# STM32G564 register map
File version: 2.0.0
CPU: CM33 r0p4, little endian, MPU, FPU, 4 interrupt priority bits
Registers are 32-bit, read-write, reset 0x0 unless marked. A register's access mark holds for its fields unless they carry their own. Offsets are from the block's base; [hi:lo] are bit positions; {n}, {i} and the like mark numbered series; 'fields as' and 'values as' point back to an identical list.

## TIM1 — TIM address block description
Base 0x40012C00
Same registers: TIM8 0x40013400, TIM20 0x44000800, TIM1_S 0x50012C00, TIM8_S 0x50013400, TIM20_S 0x54000800
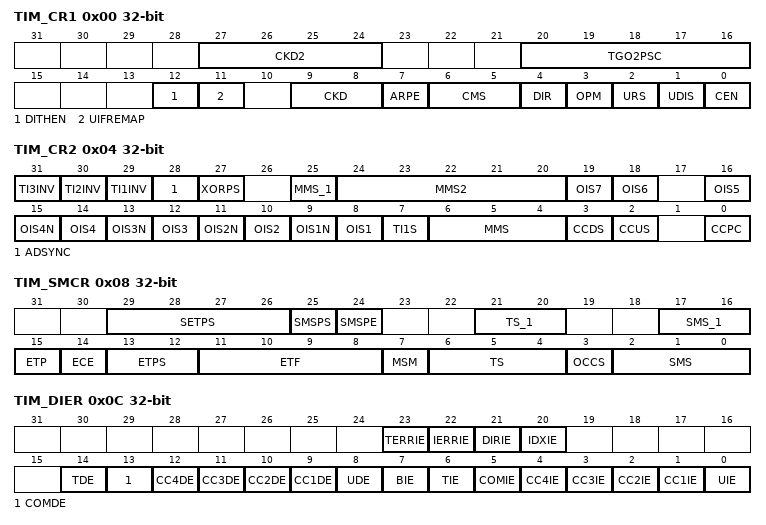
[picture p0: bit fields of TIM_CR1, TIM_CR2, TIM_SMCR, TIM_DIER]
0x00 TIM_CR1 — TIM control register 1
  [27:24] CKD2 — Clock division 2
    0=No Division; 1=tless thansub>DTS2less than/sub> = 4*tless thansub>DTSless than/sub>; 2=tless thansub>DTS2less than/sub> = 16*tless thansub>DTSless than/sub>; 3=tless thansub>DTS2less than/sub> = 64*tless thansub>DTSless than/sub>; 4=tless thansub>DTS2less than/sub> = 256*tless thansub>DTSless than/sub>; 5=tless thansub>DTS2less than/sub> = 1024*tless thansub>DTSless than/sub>; 6=tless thansub>DTS2less than/sub> = 4096*tless thansub>DTSless than/sub>; 7=tless thansub>DTS2less than/sub> = 16384*tless thansub>DTSless than/sub>; 8=tless thansub>DTS2less than/sub> = 65536*tless thansub>DTSless than/sub>; 9=tless thansub>DTS2less than/sub> = 262144*tless thansub>DTSless than/sub>
  [20:16] TGO2PSC — Trigger output 2 postcaler
  [12] DITHEN — Dithering enable
    0=Dithering disabled; 1=Dithering enabled
  [11] UIFREMAP — UIF status bit remapping
    0=No remapping. UIF status bit is not copied to TIMx_CNT register bit 31.; 1=Remapping enabled. UIF status bit is copied to TIMx_CNT register bit 31.
  [9:8] CKD — Clock division
    0=tless thansub>DTSless than/sub> = tless thansub>tim_ker_ckless than/sub>; 1=tless thansub>DTSless than/sub> = 2*tless thansub>tim_ker_ckless than/sub>; 2=tless thansub>DTSless than/sub> = 4*tless thansub>tim_ker_ckless than/sub>; 3=tless thansub>DTSless than/sub> = 8*tless thansub>tim_ker_ckless than/sub>
  [7] ARPE — Autoreload preload enable
    0=TIMx_ARR register is not buffered; 1=TIMx_ARR register is buffered
  [6:5] CMS — Center-aligned mode selection
    0=Edge-aligned mode. The counter counts up or down depending on the direction bit (DIR).; 1=Center-aligned mode 1. The counter counts up and down alternatively. Output compare interrupt flags of channels configured in output (CCxS = 00 in TIMx_CCMRx register) are set only when the counter is counting down.; 2=Center-aligned mode 2. The counter counts up and down alternatively. Output compare interrupt flags of channels configured in output (CCxS = 00 in TIMx_CCMRx register) are set only when the counter is counting up.; 3=Center-aligned mode 3. The counter counts up and down alternatively. Output compare interrupt flags of channels configured in output (CCxS = 00 in TIMx_CCMRx register) are set both when the counter is counting up or down.
  [4] DIR — Direction
    0=Counter used as upcounter; 1=Counter used as downcounter
  [3] OPM — One-pulse mode
    0=Counter is not stopped at update event; 1=Counter stops counting at the next update event (clearing the bit CEN)
  [2] URS — Update request source
    0=Any of the following events generate an update interrupt or DMA request if enabled. These events can be:; 1=Only counter overflow/underflow generates an update interrupt or DMA request if enabled
  [1] UDIS — Update disable
    0=UEV enabled. The Update (UEV) event is generated by one of the following events:; 1=UEV disabled. The Update event is not generated, shadow registers keep their value (ARR, PSC, CCRx). However the counter and the prescaler are reinitialized if the UG bit is set or if a hardware reset is received from the slave mode controller.
  [0] CEN — Counter enable
    0=Counter disabled; 1=Counter enabled
0x04 TIM_CR2 — TIM control register 2
  [31] TI3INV — tim_ti3 signal inversion on XOR gate input
    0=tim_ti3 non-inverted; 1=tim_ti3 inverted
  [30] TI2INV — tim_ti2 signal inversion on XOR gate input
    0=tim_ti2 non-inverted; 1=tim_ti2 inverted
  [29] TI1INV — tim_ti1 signal inversion on XOR gate input
    0=tim_ti1 non-inverted; 1=tim_ti1 inverted
  [28] ADSYNC — ADC synchronization
    0=The timer operates independently from the ADC; 1=The timer operation is synchronized with the ADC clock to provide jitter-free sampling point. This mode can be enabled only with specific ADC / timer clock relationship. Refer to Section204.3.37 for requirements.
  [27] XORPS — XOR gate position selection
    0=XOR gate placed before TI1 filter; 1=XOR gate placed after TI1, TI2 and TI3 filters
  [25] MMS_1 — MMS[3]
  [24:20] MMS2 — Master mode selection 2
    0=Reset - the UG bit from the TIMx_EGR register is used as trigger output (tim_trgo2). If the reset is generated by the trigger input (slave mode controller configured in reset mode), the signal on tim_trgo2 is delayed compared to the actual reset.; 1=Enable - the Counter Enable signal CNT_EN is used as trigger output (tim_trgo2). It is useful to start several timers at the same time or to control a window in which a slave timer is enabled. The Counter Enable signal is generated by a logic AND between the CEN control bit and the trigger input when configured in Gated mode. When the Counter Enable signal is controlled by the trigger input, there is a delay on tim_trgo2, except if the Master/Slave mode is selected (see the MSM bit description in TIMx_SMCR register).; 2=Update - the update event is selected as trigger output (tim_trgo2). For instance, a master timer can then be used as a prescaler for a slave timer.; 3=Compare pulse - the trigger output sends a positive pulse when the CC1IF flag is to be set (even if it was already high), as soon as a capture or compare match occurs (tim_trgo2); {v}=Compare - tim_oc{v-3}refc signal is used as trigger output (tim_trgo2) (v=4..9); 10=Compare Pulse - tim_oc4refc rising or falling edges generate pulses on tim_trgo2; 11=Compare pulse - tim_oc6refc rising or falling edges generate pulses on tim_trgo2; 12=Compare pulse - tim_oc4refc or tim_oc6refc rising edges generate pulses on tim_trgo2; 13=Compare pulse - tim_oc4refc rising or tim_oc6refc falling edges generate pulses on tim_trgo2; 14=Compare pulse - tim_oc5refc or tim_oc6refc rising edges generate pulses on tim_trgo2; 15=Compare pulse - tim_oc5refc rising or tim_oc6refc falling edges generate pulses on tim_trgo2; 16=Compare - tim_oc7refc signal is used as trigger output (tim_trgo2); 17=Compare Pulse - tim_oc7refc rising or falling edges generate pulses on tim_trgo2; 18=Compare Pulse tim_oc4refc or tim_oc7efc rising edges generate pulses on tim_trgo2; 19=Compare Pulse - tim_oc4refc rising or tim_oc7refc falling edges generate pulses on tim_trgo2; 20=Compare Pulse -tim_oc5refc or tim_oc7efc rising edges generate pulses on tim_trgo2; 21=Compare Pulse - tim_oc5refc rising or tim_oc7refc falling edges generate pulses on tim_trgo2; 22=Compare Pulse - tim_oc6refc or tim_oc7efc rising edges generate pulses on tim_trgo2; 23=Compare Pulse - tim_oc6refc rising or tim_oc7refc falling edges generate pulses on tim_trgo2
  [19] OIS7 — Output idle state 7 (tim_oc7 output)
  [18] OIS6 — Output idle state 6 (tim_oc6 output)
  [16] OIS5 — Output idle state 5 (tim_oc5 output)
  [15] OIS4N — Output idle state 4 (tim_oc4n output)
  [14] OIS4 — Output idle state 4 (tim_oc4 output)
  [13] OIS3N — Output idle state 3 (tim_oc3n output)
  [12] OIS3 — Output idle state 3 (tim_oc3n output)
  [11] OIS2N — Output idle state 2 (tim_oc2n output)
  [10] OIS2 — Output idle state 2 (tim_oc2 output)
  [9] OIS1N — Output idle state 1 (tim_oc1n output)
    0=tim_oc1n = 0 after a dead-time when MOE = 0; 1=tim_oc1n = 1 after a dead-time when MOE = 0
  [8] OIS1 — Output idle state 1 (tim_oc1 output)
    0=tim_oc1 = 0 (after a dead-time) when MOE = 0; 1=tim_oc1 = 1 (after a dead-time) when MOE = 0
  [7] TI1S — tim_ti1 selection
    0=The tim_ti1_in[15:0] multiplexer output is connected to tim_ti1 input; 1=tim_ti1_in[15:0], tim_ti2_in[15:0] and tim_ti3_in[15:0] multiplexers outputs are XORed and connected to the tim_ti1 input
  [6:4] MMS — MMS[2:0]: Master mode selection
    0=Reset - the UG bit from the TIMx_EGR register is used as trigger output (tim_trgo). If the reset is generated by the trigger input (slave mode controller configured in reset mode) then the signal on tim_trgo is delayed compared to the actual reset.; 1=Enable - the Counter Enable signal CNT_EN is used as trigger output (tim_trgo). It is useful to start several timers at the same time or to control a window in which a slave timer is enable. The Counter Enable signal is generated by a logic AND between CEN control bit and the trigger input when configured in gated mode. When the Counter Enable signal is controlled by the trigger input, there is a delay on tim_trgo, except if the master/slave mode is selected (see the MSM bit description in TIMx_SMCR register).; 2=Update - The update event is selected as trigger output (tim_trgo). For instance a master timer can then be used as a prescaler for a slave timer.; 3=Compare Pulse - The trigger output send a positive pulse when the CC1IF flag is to be set (even if it was already high), as soon as a capture or a compare match occurred. (tim_trgo).; {v}=Compare - tim_oc{v-3}refc signal is used as trigger output (tim_trgo) (v=4..7)
  [3] CCDS — Capture/compare DMA selection
    0=CCx DMA request sent when CCx event occurs; 1=CCx DMA requests sent when update event occurs
  [2] CCUS — Capture/compare control update selection
    0=When capture/compare control bits are preloaded (CCPC = 1), they are updated by setting the COMG bit only; 1=When capture/compare control bits are preloaded (CCPC = 1), they are updated by setting the COMG bit or when an rising edge occurs on tim_trgi
  [0] CCPC — Capture/compare preloaded control
    0=CCxE, CCxNE, CCxP, CCxNP and OCxM bits are not preloaded; 1=CCxE, CCxNE, CCxP, CCxNP and OCxM bits are preloaded, after having been written, they are updated only when a commutation event (COM) occurs (COMG bit set or rising edge detected on tim_trgi, depending on the CCUS bit)
0x08 TIM_SMCR — TIM slave mode control register
  [29:26] SETPS — Synchronous external trigger prescaler
  [25] SMSPS — SMS preload source
    0=The transfer is triggered by the Timer's Update event; 1=The transfer is triggered by the Index event
  [24] SMSPE — SMS preload enable
    0=SMS[4:0] bit field is not preloaded; 1=SMS[4:0] preload is enabled
  [21:20] TS_1 — TS[4:3]
  [17:16] SMS_1 — SMS[4:3]
  [15] ETP — External trigger polarity
    0=tim_etr_in is non-inverted, active at high level or rising edge; 1=tim_etr_in is inverted, active at low level or falling edge
  [14] ECE — External clock enable
    0=External clock mode 2 disabled; 1=External clock mode 2 enabled. The counter is clocked by any active edge on the tim_etrf signal.
  [13:12] ETPS — External trigger prescaler
    0=Prescaler OFF; 1=tim_etr_in frequency divided by 2; 2=tim_etr_in frequency divided by 4; 3=tim_etr_in frequency divided by 8
  [11:8] ETF — External trigger filter
    0=No filter, sampling is done at fless thansub>DTS2less than/sub>; 1=fless thansub>SAMPLINGless than/sub> = fless thansub>tim_ker_ckless than/sub>, N = 2; 2=fless thansub>SAMPLINGless than/sub> = fless thansub>tim_ker_ckless than/sub>, N = 4; 3=fless thansub>SAMPLINGless than/sub> = fless thansub>tim_ker_ckless than/sub>, N = 8; 4=fless thansub>SAMPLINGless than/sub> = fless thansub>DTS2less than/sub>/2, N = 6; 5=fless thansub>SAMPLINGless than/sub> = fless thansub>DTS2less than/sub>/2, N = 8; 6=fless thansub>SAMPLINGless than/sub> = fless thansub>DTS2less than/sub>/4, N = 6; 7=fless thansub>SAMPLINGless than/sub> = fless thansub>DTS2less than/sub>/4, N = 8; 8=fless thansub>SAMPLINGless than/sub> = fless thansub>DTS2less than/sub>/8, N = 6; 9=fless thansub>SAMPLINGless than/sub> = fless thansub>DTS2less than/sub>/8, N = 8; 10=fless thansub>SAMPLINGless than/sub> = fless thansub>DTS2less than/sub>/16, N = 5; 11=fless thansub>SAMPLINGless than/sub> = fless thansub>DTS2less than/sub>/16, N = 6; 12=fless thansub>SAMPLINGless than/sub> = fless thansub>DTS2less than/sub>/16, N = 8; 13=fless thansub>SAMPLINGless than/sub> = fless thansub>DTS2less than/sub>/32, N = 5; 14=fless thansub>SAMPLINGless than/sub> = fless thansub>DTS2less than/sub>/32, N = 6; 15=fless thansub>SAMPLINGless than/sub> = fless thansub>DTS2less than/sub>/32, N = 8
  [7] MSM — Master/slave mode
    0=No action; 1=The effect of an event on the trigger input (tim_trgi) is delayed to allow a perfect synchronization between the current timer and its slaves (through tim_trgo). It is useful if we want to synchronize several timers on a single external event.
  [6:4] TS — TS[2:0]: Trigger selection
    {v}=Internal trigger {v} (tim_itr{v}) (v=0..3); 4=tim_ti1 Edge Detector (tim_ti1f_ed); 5=Filtered Timer Input 1 (tim_ti1fp1); 6=Filtered Timer Input 2 (tim_ti2fp2); 7=External trigger input (tim_etrf)
  [3] OCCS — OCREF clear selection
    0=tim_ocref_clr_int is connected to the tim_ocref_clr input; 1=tim_ocref_clr_int is connected to tim_etrf
  [2:0] SMS — SMS[2:0]: Slave mode selection
    0=Slave mode disabled - if CEN = 1 then the prescaler is clocked directly by the internal clock; 1=Quadrature encoder mode 1, x2 mode- Counter counts up/down on tim_ti1fp1 edge depending on tim_ti2fp2 level; 2=Quadrature encoder mode 2, x2 mode - Counter counts up/down on tim_ti2fp2 edge depending on tim_ti1fp1 level; 3=Quadrature encoder mode 3, x4 mode - Counter counts up/down on both tim_ti1fp1 and tim_ti2fp2 edges depending on the level of the other input; 4=Reset mode - Rising edge of the selected trigger input (tim_trgi) reinitializes the counter and generates an update of the registers; 5=Gated mode - The counter clock is enabled when the trigger input (tim_trgi) is high. The counter stops (but is not reset) as soon as the trigger becomes low. Both start and stop of the counter are controlled.; 6=Trigger mode - The counter starts at a rising edge of the trigger tim_trgi (but it is not reset). Only the start of the counter is controlled.; 7=External Clock mode 1 - Rising edges of the selected trigger (tim_trgi) clock the counter
0x0C TIM_DIER — TIM DMA/interrupt enable register
  [23] TERRIE — Transition error interrupt enable
    0=Transition error interrupt disabled; 1=Transition error interrupt enabled
  [22] IERRIE — Index error interrupt enable
    0=Index error interrupt disabled; 1=Index error interrupt enabled
  [21] DIRIE — Direction change interrupt enable
    0=Direction Change interrupt disabled; 1=Direction Change interrupt enabled
  [20] IDXIE — Index interrupt enable
    0=Index interrupt disabled; 1=Index Change interrupt enabled
  [14] TDE — Trigger DMA request enable
    0=Trigger DMA request disabled; 1=Trigger DMA request enabled
  [13] COMDE — COM DMA request enable
    0=COM DMA request disabled; 1=COM DMA request enabled
  [n+8] CC{n}DE (n=1..4) — Capture/compare {n} DMA request enable
    0=CC{n} DMA request disabled; 1=CC{n} DMA request enabled
  [8] UDE — Update DMA request enable
    0=Update DMA request disabled; 1=Update DMA request enabled
  [7] BIE — Break interrupt enable
    0=Break interrupt disabled; 1=Break interrupt enabled
  [6] TIE — Trigger interrupt enable
    0=Trigger interrupt disabled; 1=Trigger interrupt enabled
  [5] COMIE — COM interrupt enable
    0=COM interrupt disabled; 1=COM interrupt enabled
  [n] CC{n}IE (n=1..4) — Capture/compare {n} interrupt enable
    0=CC{n} interrupt disabled; 1=CC{n} interrupt enabled
  [0] UIE — Update interrupt enable
    0=Update interrupt disabled; 1=Update interrupt enabled
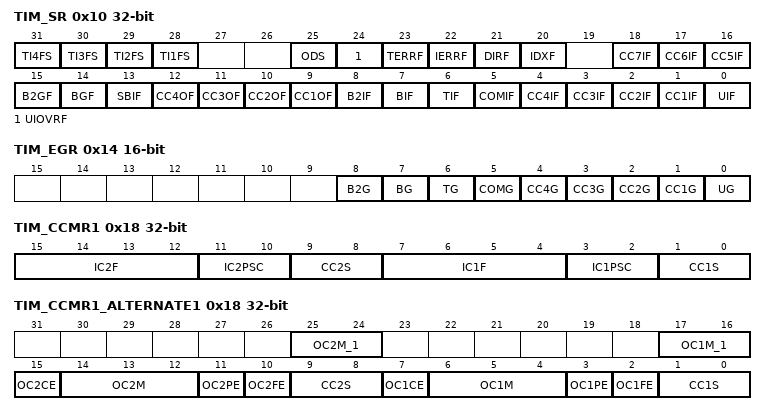
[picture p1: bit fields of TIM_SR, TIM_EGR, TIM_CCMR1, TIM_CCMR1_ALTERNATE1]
0x10 TIM_SR — TIM status register
  [n+27] TI{n}FS ro (n=1..4) — tim_ti{n}f status
    0=tim_ti{n}f signal is low; 1=tim_ti{n}f signal is high
  [25] ODS ro — Output disable status
    0=Idle state: break was triggered (or MOE was written to 0), and OIS states are forced on tim_ocx and tim_ocxn outputs; 1=Disabled state: break2 was triggered, tim_ocx and tim_ocxn outputs are inactive
  [24] UIOVRF — Update Interrupt Overrun flag
    0=No Update Interrupt Overrun; 1=Update Interrupt Overrun
  [23] TERRF — Transition error interrupt flag
    0=No encoder transition error has been detected; 1=An encoder transition error has been detected
  [22] IERRF — Index error interrupt flag
    0=No index error has been detected; 1=An index error has been detected
  [21] DIRF — Direction change interrupt flag
    0=No direction change; 1=Direction change
  [20] IDXF — Index interrupt flag
    0=No index event occurred; 1=An index event has occurred
  [18] CC7IF — Compare 7 interrupt flag
  [17] CC6IF — Compare 6 interrupt flag
  [16] CC5IF — Compare 5 interrupt flag
  [15] B2GF — Break 2 generation flag
    0=No break 2 event occurred; 1=A break 2 event was forced with the B2G bit
  [14] BGF — Break generation flag
    0=No break event occurred; 1=A break event was forced with the BG bit
  [13] SBIF — System break interrupt flag
    0=No break event occurred; 1=An active level has been detected on the system break input. An interrupt is generated if BIE = 1 in the TIMx_DIER register.
  [12] CC4OF — Capture/compare 4 overcapture flag
  [11] CC3OF — Capture/compare 3 overcapture flag
  [10] CC2OF — Capture/compare 2 overcapture flag
  [9] CC1OF — Capture/compare 1 overcapture flag
    0=No overcapture has been detected; 1=The counter value has been captured in TIMx_CCR1 register while CC1IF flag was already set
  [8] B2IF — Break 2 interrupt flag
    0=No break event occurred; 1=An active level has been detected on the break 2 input. An interrupt is generated if BIE=1 in the TIMx_DIER register.
  [7] BIF — Break interrupt flag
    0=No break event occurred; 1=An active level has been detected on the break input. An interrupt is generated if BIE = 1 in the TIMx_DIER register.
  [6] TIF — Trigger interrupt flag
    0=No trigger event occurred; 1=Trigger interrupt pending
  [5] COMIF — COM interrupt flag
    0=No COM event occurred; 1=COM interrupt pending
  [4] CC4IF — Capture/compare 4 interrupt flag
  [3] CC3IF — Capture/compare 3 interrupt flag
  [2] CC2IF — Capture/compare 2 interrupt flag
  [1] CC1IF — Capture/compare 1 interrupt flag
    0=No compare match / No input capture occurred; 1=A compare match or an input capture occurred
  [0] UIF — Update interrupt flag
    0=No update occurred; 1=Update interrupt pending. This bit is set by hardware when the registers are updated:
0x14 TIM_EGR 16-bit wo — TIM event generation register
  [8] B2G — Break 2 generation
    0=No action; 1=A break 2 event is generated. MOE bit is cleared and B2IF flag is set. Related interrupt can occur if enabled.
  [7] BG — Break generation
    0=No action; 1=A break event is generated. MOE bit is cleared and BIF flag is set. Related interrupt or DMA transfer can occur if enabled.
  [6] TG — Trigger generation
    0=No action; 1=The TIF flag is set in TIMx_SR register. Related interrupt or DMA transfer can occur if enabled.
  [5] COMG — Capture/compare control update generation
    0=No action; 1=CCxE, CCxNE and OCxM bits update (providing CCPC bit is set)
  [4] CC4G — Capture/compare 4 generation
  [3] CC3G — Capture/compare 3 generation
  [2] CC2G — Capture/compare 2 generation
  [1] CC1G — Capture/compare 1 generation
    0=No action; 1=A capture/compare event is generated on channel 1:
  [0] UG — Update generation
    0=No action; 1=Reinitialize the counter and generates an update of the registers. Note that the prescaler counter is cleared too (anyway the prescaler ratio is not affected). The counter is cleared if the center-aligned mode is selected or if DIR = 0 (upcounting), else it takes the autoreload value (TIMx_ARR) if DIR = 1 (downcounting).
0x18 TIM_CCMR1 — TIM capture/compare mode register 1
  [15:12] IC2F — Input capture 2 filter
  [11:10] IC2PSC — Input capture 2 prescaler
  [9:8] CC2S — Capture/compare 2 selection
    0=CC2 channel is configured as output; 1=CC2 channel is configured as input, tim_ic2 is mapped on tim_ti2; 2=CC2 channel is configured as input, tim_ic2 is mapped on tim_ti1; 3=CC2 channel is configured as input, tim_ic2 is mapped on tim_trc. This mode is working only if an internal trigger input is selected through TS bit (TIMx_SMCR register)
  [7:4] IC1F — Input capture 1 filter
    values as TIM_SMCR.ETF
  [3:2] IC1PSC — Input capture 1 prescaler
    0=no prescaler, capture is done each time an edge is detected on the capture input; 1=capture is done once every 2 events; 2=capture is done once every 4 events; 3=capture is done once every 8 events
  [1:0] CC1S — Capture/compare 1 Selection
    0=CC1 channel is configured as output; 1=CC1 channel is configured as input, tim_ic1 is mapped on tim_ti1; 2=CC1 channel is configured as input, tim_ic1 is mapped on tim_ti2; 3=CC1 channel is configured as input, tim_ic1 is mapped on tim_trc. This mode is working only if an internal trigger input is selected through TS bit (TIMx_SMCR register)
0x18 TIM_CCMR1_ALTERNATE1 (alternate view of TIM_CCMR1) — TIM capture/compare mode register 1
  [25:24] OC2M_1 — OC2M[4:3]
  [17:16] OC1M_1 — OC1M[4:3]
  [15] OC2CE — Output compare 2 clear enable
    0=tim_oc2ref is not affected by the tim_ocref_clr_int signal; 1=tim_oc2ref is cleared as soon as a High level is detected on tim_ocref_clr_int signal (tim_ocref_clr input or tim_etrf input)
  [14:12] OC2M — OC2M[2:0]: Output compare 2 mode
  [11] OC2PE — Output compare 2 preload enable
    0=Preload register on TIMx_CCR2 disabled. TIMx_CCR2 can be written at anytime, the new value is taken in account immediately.; 1=Preload register on TIMx_CCR2 enabled. Read/Write operations access the preload register. TIMx_CCR2 preload value is loaded in the active register at each update event.
  [10] OC2FE — Output compare 2 fast enable
    0=CC2 behaves normally depending on counter and CCR2 values even when the trigger is ON. The minimum delay to activate CC2 output when an edge occurs on the trigger input is 5 clock cycles.; 1=An active edge on the trigger input acts like a compare match on CC2 output. Then, OC is set to the compare level independently from the result of the comparison. Delay to sample the trigger input and to activate CC2 output is reduced to 3 clock cycles. OCFE acts only if the channel is configured in PWM1 or PWM2 mode.
  [9:8] CC2S — Capture/compare 2 selection
    0=CC2 channel is configured as output; 1=CC2 channel is configured as input, tim_ic2 is mapped on tim_ti2; 2=CC2 channel is configured as input, tim_ic2 is mapped on tim_ti1; 3=CC2 channel is configured as input, tim_ic2 is mapped on tim_trc. This mode is working only if an internal trigger input is selected through the TS bit (TIMx_SMCR register)
  [7] OC1CE — Output compare 1 clear enable
    0=tim_oc1ref is not affected by the tim_ocref_clr_int signal; 1=tim_oc1ref is cleared as soon as a High level is detected on tim_ocref_clr_int signal (tim_ocref_clr input or tim_etrf input)
  [6:4] OC1M — OC1M[2:0]: Output compare 1 mode
    0=Frozen - The comparison between the output compare register TIMx_CCR1 and the counter TIMx_CNT has no effect on the outputs.This mode can be used when the timer serves as a software timebase. When the frozen mode is enabled during timer operation, the output keeps the state (active or inactive) it had before entering the frozen state.; 1=Set channel 1 to active level on match. tim_oc1ref signal is forced high when the counter TIMx_CNT matches the capture/compare register 1 (TIMx_CCR1).; 2=Set channel 1 to inactive level on match. tim_oc1ref signal is forced low when the counter TIMx_CNT matches the capture/compare register 1 (TIMx_CCR1).; 3=Toggle - tim_oc1ref toggles when TIMx_CNT = TIMx_CCR1; 4=Force inactive level - tim_oc1ref is forced low; 5=Force active level - tim_oc1ref is forced high; 6=PWM mode 1 - In upcounting, channel 1 is active as long as TIMx_CNTless thanTIMx_CCR1 else inactive. In downcounting, channel 1 is inactive (tim_oc1ref = 0) as long as TIMx_CNT>TIMx_CCR1 else active (tim_oc1ref = 1).; 7=PWM mode 2 - In upcounting, channel 1 is inactive as long as TIMx_CNTless thanTIMx_CCR1 else active. In downcounting, channel 1 is active as long as TIMx_CNT>TIMx_CCR1 else inactive.
  [3] OC1PE — Output compare 1 preload enable
    0=Preload register on TIMx_CCR1 disabled. TIMx_CCR1 can be written at anytime, the new value is taken in account immediately.; 1=Preload register on TIMx_CCR1 enabled. Read/Write operations access the preload register. TIMx_CCR1 preload value is loaded in the active register at each update event.
  [2] OC1FE — Output compare 1 fast enable
    0=CC1 behaves normally depending on counter and CCR1 values even when the trigger is ON. The minimum delay to activate CC1 output when an edge occurs on the trigger input is 5 clock cycles.; 1=An active edge on the trigger input acts like a compare match on CC1 output. Then, OC is set to the compare level independently from the result of the comparison. Delay to sample the trigger input and to activate CC1 output is reduced to 3 clock cycles. OCFE acts only if the channel is configured in PWM1 or PWM2 mode.
  [1:0] CC1S — Capture/compare 1 selection
    values as TIM_CCMR1.CC1S
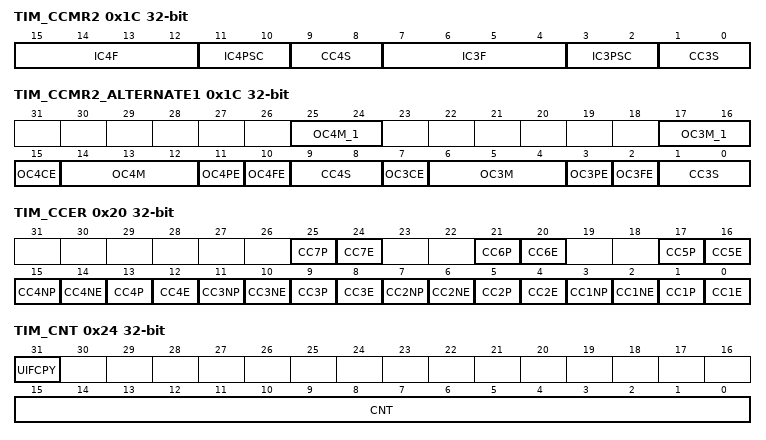
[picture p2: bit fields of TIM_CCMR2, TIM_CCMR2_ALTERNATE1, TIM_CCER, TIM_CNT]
0x1C TIM_CCMR2 — TIM capture/compare mode register 2
  [15:12] IC4F — Input capture 4 filter
  [11:10] IC4PSC — Input capture 4 prescaler
  [9:8] CC4S — Capture/compare 4 selection
    0=CC4 channel is configured as output; 1=CC4 channel is configured as input, tim_ic4 is mapped on tim_ti4; 2=CC4 channel is configured as input, tim_ic4 is mapped on tim_ti3; 3=CC4 channel is configured as input, tim_ic4 is mapped on tim_trc. This mode is working only if an internal trigger input is selected through TS bit (TIMx_SMCR register)
  [7:4] IC3F — Input capture 3 filter
    values as TIM_SMCR.ETF
  [3:2] IC3PSC — Input capture 3 prescaler
    values as TIM_CCMR1.IC1PSC
  [1:0] CC3S — Capture/compare 3 selection
    0=CC3 channel is configured as output; 1=CC3 channel is configured as input, tim_ic3 is mapped on tim_ti3; 2=CC3 channel is configured as input, tim_ic3 is mapped on tim_ti4; 3=CC3 channel is configured as input, tim_ic3 is mapped on tim_trc. This mode is working only if an internal trigger input is selected through TS bit (TIMx_SMCR register)
0x1C TIM_CCMR2_ALTERNATE1 (alternate view of TIM_CCMR2) — TIM capture/compare mode register 2
  [25:24] OC4M_1 — OC4M[4:3]
  [17:16] OC3M_1 — OC3M[4:3]
  [15] OC4CE — Output compare 4 clear enable
    0=tim_oc4ref is not affected by the tim_ocref_clr_int signal; 1=tim_oc4ref is cleared as soon as a High level is detected on tim_ocref_clr_int signal (tim_ocref_clr input or tim_etrf input)
  [14:12] OC4M — OC4M[2:0]: Output compare 4 mode
  [11] OC4PE — Output compare 4 preload enable
    0=Preload register on TIMx_CCR4 disabled. TIMx_CCR4 can be written at anytime, the new value is taken in account immediately.; 1=Preload register on TIMx_CCR4 enabled. Read/Write operations access the preload register. TIMx_CCR4 preload value is loaded in the active register at each update event.
  [10] OC4FE — Output compare 4 fast enable
    0=CC4 behaves normally depending on counter and CCR4 values even when the trigger is ON. The minimum delay to activate CC4 output when an edge occurs on the trigger input is 5 clock cycles.; 1=An active edge on the trigger input acts like a compare match on CC4 output. Then, OC is set to the compare level independently from the result of the comparison. Delay to sample the trigger input and to activate CC4 output is reduced to 3 clock cycles. OCFE acts only if the channel is configured in PWM1 or PWM2 mode.
  [9:8] CC4S — Capture/compare 4 selection
    values as TIM_CCMR2.CC4S
  [7] OC3CE — Output compare 3 clear enable
    0=tim_oc3ref is not affected by the tim_ocref_clr_int signal; 1=tim_oc3ref is cleared as soon as a High level is detected on tim_ocref_clr_int signal (tim_ocref_clr input or tim_etrf input)
  [6:4] OC3M — OC3M[2:0]: Output compare 3 mode
    0=Frozen - The comparison between the output compare register TIMx_CCR3 and the counter TIMx_CNT has no effect on the outputs.(this mode is used to generate a timing base); 1=Set channel 3 to active level on match. tim_oc3ref signal is forced high when the counter TIMx_CNT matches the capture/compare register 3 (TIMx_CCR3).; 2=Set channel 3 to inactive level on match. tim_oc3ref signal is forced low when the counter TIMx_CNT matches the capture/compare register 3 (TIMx_CCR3).; 3=Toggle - tim_oc3ref toggles when TIMx_CNT = TIMx_CCR3; 4=Force inactive level - tim_oc3ref is forced low; 5=Force active level - tim_oc3ref is forced high; 6=PWM mode 1 - In upcounting, channel 3 is active as long as TIMx_CNTless thanTIMx_CCR3 else inactive. In downcounting, channel 3 is inactive (tim_oc3ref = 0) as long as TIMx_CNT>TIMx_CCR3 else active (tim_oc3ref = 1).; 7=PWM mode 2 - In upcounting, channel 3 is inactive as long as TIMx_CNTless thanTIMx_CCR3 else active. In downcounting, channel 3 is active as long as TIMx_CNT>TIMx_CCR3 else inactive.
  [3] OC3PE — Output compare 3 preload enable
    0=Preload register on TIMx_CCR3 disabled. TIMx_CCR3 can be written at anytime, the new value is taken in account immediately.; 1=Preload register on TIMx_CCR3 enabled. Read/Write operations access the preload register. TIMx_CCR3 preload value is loaded in the active register at each update event.
  [2] OC3FE — Output compare 3 fast enable
    0=CC3 behaves normally depending on counter and CCR3 values even when the trigger is ON. The minimum delay to activate CC3 output when an edge occurs on the trigger input is 5 clock cycles.; 1=An active edge on the trigger input acts like a compare match on CC3 output. Then, OC is set to the compare level independently from the result of the comparison. Delay to sample the trigger input and to activate CC3 output is reduced to 3 clock cycles. OCFE acts only if the channel is configured in PWM1 or PWM2 mode.
  [1:0] CC3S — Capture/compare 3 selection
    values as TIM_CCMR2.CC3S
0x20 TIM_CCER — TIM capture/compare enable register
  [4n-3] CC{n}P (n=2..7) — Capture/compare {n} output polarity
  [4n-4] CC{n}E (n=2..7) — Capture/compare {n} output enable
  [15] CC4NP — Capture/compare 4 complementary output polarity
  [14] CC4NE — Capture/compare 4 complementary output enable
  [11] CC3NP — Capture/compare 3 complementary output polarity
  [10] CC3NE — Capture/compare 3 complementary output enable
  [7] CC2NP — Capture/compare 2 complementary output polarity
  [6] CC2NE — Capture/compare 2 complementary output enable
  [3] CC1NP — Capture/compare 1 complementary output polarity
    0=tim_oc1n active high; 1=tim_oc1n active low
  [2] CC1NE — Capture/compare 1 complementary output enable
    0=Off - tim_oc1n is not active. tim_oc1n level is then function of MOE, OSSI, OSSR, OIS1, OIS1N and CC1E bits.; 1=On - tim_oc1n signal is output on the corresponding output pin depending on MOE, OSSI, OSSR, OIS1, OIS1N and CC1E bits
  [1] CC1P — Capture/compare 1 output polarity
    0=OC1 active high (output mode) / Edge sensitivity selection (input mode, see below); 1=OC1 active low (output mode) / Edge sensitivity selection (input mode, see below)
  [0] CC1E — Capture/compare 1 output enable
    0=Capture mode disabled / OC1 is not active (see below); 1=Capture mode enabled / OC1 signal is output on the corresponding output pin
0x24 TIM_CNT — TIM counter
  [31] UIFCPY ro — UIF copy
  [15:0] CNT — Counter value
0x28 TIM_PSC 16-bit — TIM prescaler
  [15:0] PSC — Prescaler value
0x2C TIM_ARR reset 0xFFFF — TIM autoreload register
  [19:0] ARR — Autoreload value
0x30 TIM_RCR 16-bit — TIM repetition counter register
  [15:0] REP — Repetition counter reload value
0x34 TIM_CCR1 — TIM capture/compare register 1
  [19:0] CCR1 — Capture/compare 1 value
0x38 TIM_CCR2 — TIM capture/compare register 2
  [19:0] CCR2 — Capture/compare 2 value
0x3C TIM_CCR3 — TIM capture/compare register 3
  [19:0] CCR3 — Capture/compare value
0x40 TIM_CCR4 — TIM capture/compare register 4
  [19:0] CCR4 — Capture/compare value
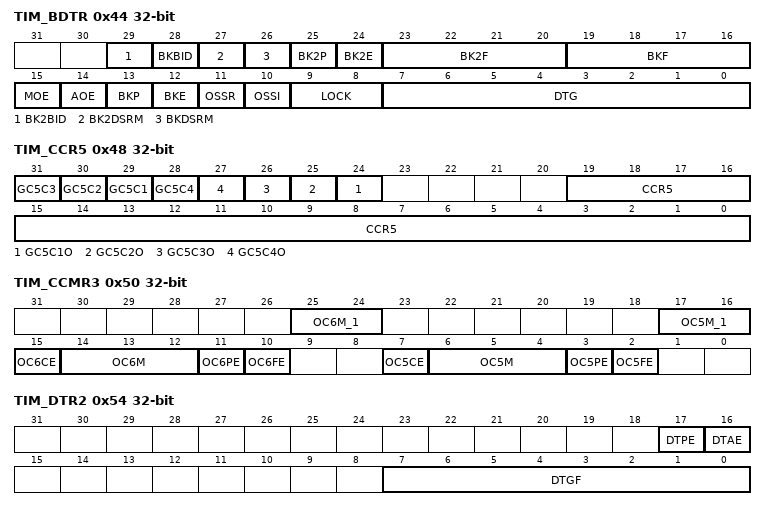
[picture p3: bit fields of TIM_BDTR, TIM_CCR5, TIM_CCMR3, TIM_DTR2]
0x44 TIM_BDTR — TIM break and dead-time register
  [29] BK2BID — Break2 bidirectional
  [28] BKBID — Break bidirectional
    0=Break input tim_brk in input mode; 1=Break input tim_brk in bidirectional mode
  [27] BK2DSRM — Break2 disarm
  [26] BKDSRM — Break disarm
    0=Break input tim_brk is armed; 1=Break input tim_brk is disarmed
  [25] BK2P — Break 2 polarity
    0=Break input tim_brk2 is active low; 1=Break input tim_brk2 is active high
  [24] BK2E — Break 2 enable
    0=Break2 function disabled; 1=Break2 function enabled
  [23:20] BK2F — Break 2 filter
    0=No filter, tim_brk2 acts asynchronously; 1=fless thansub>SAMPLINGless than/sub> = fless thansub>tim_ker_ckless than/sub>, N = 2; 2=fless thansub>SAMPLINGless than/sub> = fless thansub>tim_ker_ckless than/sub>, N = 4; 3=fless thansub>SAMPLINGless than/sub> = fless thansub>tim_ker_ckless than/sub>, N = 8; 4=fless thansub>SAMPLINGless than/sub> = fless thansub>DTSless than/sub>/2, N = 6; 5=fless thansub>SAMPLINGless than/sub> = fless thansub>DTSless than/sub>/2, N = 8; 6=fless thansub>SAMPLINGless than/sub> = fless thansub>DTSless than/sub>/4, N = 6; 7=fless thansub>SAMPLINGless than/sub> = fless thansub>DTSless than/sub>/4, N = 8; 8=fless thansub>SAMPLINGless than/sub> = fless thansub>DTSless than/sub>/8, N = 6; 9=fless thansub>SAMPLINGless than/sub> = fless thansub>DTSless than/sub>/8, N = 8; 10=fless thansub>SAMPLINGless than/sub> = fless thansub>DTSless than/sub>/16, N = 5; 11=fless thansub>SAMPLINGless than/sub> = fless thansub>DTSless than/sub>/16, N = 6; 12=fless thansub>SAMPLINGless than/sub> = fless thansub>DTSless than/sub>/16, N = 8; 13=fless thansub>SAMPLINGless than/sub> = fless thansub>DTSless than/sub>/32, N = 5; 14=fless thansub>SAMPLINGless than/sub> = fless thansub>DTSless than/sub>/32, N = 6; 15=fless thansub>SAMPLINGless than/sub> = fless thansub>DTSless than/sub>/32, N = 8
  [19:16] BKF — Break filter
    0=No filter, tim_brk acts asynchronously; 1=fless thansub>SAMPLINGless than/sub> = fless thansub>tim_ker_ckless than/sub>, N = 2; 2=fless thansub>SAMPLINGless than/sub> = fless thansub>tim_ker_ckless than/sub>, N = 4; 3=fless thansub>SAMPLINGless than/sub> = fless thansub>tim_ker_ckless than/sub>, N = 8; 4=fless thansub>SAMPLINGless than/sub> = fless thansub>DTSless than/sub>/2, N = 6; 5=fless thansub>SAMPLINGless than/sub> = fless thansub>DTSless than/sub>/2, N = 8; 6=fless thansub>SAMPLINGless than/sub> = fless thansub>DTSless than/sub>/4, N = 6; 7=fless thansub>SAMPLINGless than/sub> = fless thansub>DTSless than/sub>/4, N = 8; 8=fless thansub>SAMPLINGless than/sub> = fless thansub>DTSless than/sub>/8, N = 6; 9=fless thansub>SAMPLINGless than/sub> = fless thansub>DTSless than/sub>/8, N = 8; 10=fless thansub>SAMPLINGless than/sub> = fless thansub>DTSless than/sub>/16, N = 5; 11=fless thansub>SAMPLINGless than/sub> = fless thansub>DTSless than/sub>/16, N = 6; 12=fless thansub>SAMPLINGless than/sub> = fless thansub>DTSless than/sub>/16, N = 8; 13=fless thansub>SAMPLINGless than/sub> = fless thansub>DTSless than/sub>/32, N = 5; 14=fless thansub>SAMPLINGless than/sub> = fless thansub>DTSless than/sub>/32, N = 6; 15=fless thansub>SAMPLINGless than/sub> = fless thansub>DTSless than/sub>/32, N = 8
  [15] MOE — Main output enable
    0=In response to a break 2 event. OC and OCN outputs are disabled; 1=OC and OCN outputs are enabled if their respective enable bits are set (CCxE, CCxNE in TIMx_CCER register)
  [14] AOE — Automatic output enable
    0=MOE can be set only by software; 1=MOE can be set by software or automatically at the next update event (if none of the break inputs tim_brk and tim_brk2 is active)
  [13] BKP — Break polarity
    0=Break input tim_brk is active low; 1=Break input tim_brk is active high
  [12] BKE — Break enable
    0=Break function disabled; 1=Break function enabled
  [11] OSSR — Off-state selection for Run mode
    0=When inactive, OC/OCN outputs are disabled (the timer releases the output control which is taken over by the GPIO logic, which forces a Hi-Z state); 1=When inactive, OC/OCN outputs are enabled with their inactive level as soon as CCxE = 1 or CCxNE = 1 (the output is still controlled by the timer)
  [10] OSSI — Off-state selection for idle mode
    0=When inactive, OC/OCN outputs are disabled (the timer releases the output control which is taken over by the GPIO logic and which imposes a Hi-Z state); 1=When inactive, OC/OCN outputs are first forced with their inactive level then forced to their idle level after the deadtime. The timer maintains its control over the output.
  [9:8] LOCK — Lock configuration
    0=LOCK OFF - No bit is write protected; 1=LOCK Level 1 = DTG bits in TIMx_BDTR register, OISx and OISxN bits in TIMx_CR2 register and BKBID/BK2BID/BKE/BKP/AOE bits in TIMx_BDTR register can no longer be written; 2=LOCK Level 2 = LOCK Level 1 + CC Polarity bits (CCxP/CCxNP bits in TIMx_CCER register, as long as the related channel is configured in output through the CCxS bits) as well as OSSR and OSSI bits can no longer be written; 3=LOCK Level 3 = LOCK Level 2 + CC Control bits (OCxM and OCxPE bits in TIMx_CCMRx registers, as long as the related channel is configured in output through the CCxS bits) can no longer be written
  [7:0] DTG — Dead-time generator setup
0x48 TIM_CCR5 — TIM capture/compare register 5
  [31] GC5C3 — Group channel 5 and channel 3
    0=No effect of tim_oc5ref on tim_oc3refc; 1=tim_oc3refc is the logical AND of tim_oc3ref and tim_oc5ref
  [30] GC5C2 — Group channel 5 and channel 2
    0=No effect of tim_oc5ref on tim_oc2refc; 1=tim_oc2refc is the logical AND of tim_oc2ref and tim_oc5ref
  [29] GC5C1 — Group channel 5 and channel 1
    0=No effect of oc5ref on oc1refc; 1=oc1refc is the logical AND of oc1ref and oc5ref
  [28] GC5C4 — Group channel 5 and channel 4
    0=No effect of oc5ref on oc4refc; 1=oc4refc is the logical AND of oc4ref and oc5ref
  [n+23] GC5C{n}O (n=1..4) — Group channel 5 and channel {n} (ORed)
    0=No effect of oc5ref on oc{n}refc; 1=oc4refc is the logical OR of oc{n}ref and oc5ref
  [19:0] CCR5 — compare 5 value
0x4C TIM_CCR6 — TIM capture/compare register 6
  [19:0] CCR6 — Compare 6 value
0x50 TIM_CCMR3 — TIM capture/compare mode register 3
  [25:24] OC6M_1 — OC6M[4:3]
  [17:16] OC5M_1 — OC5M[4:3]
  [15] OC6CE — Output compare 6 clear enable
    0=tim_oc6ref is not affected by the tim_ocref_clr_int signal; 1=tim_oc6ref is cleared as soon as a High level is detected on tim_ocref_clr_int signal (tim_ocref_clr input or tim_etrf input)
  [14:12] OC6M — OC6M[2:0]: Output compare 6 mode
  [11] OC6PE — Output compare 6 preload enable
    0=Preload register on TIMx_CCR6 disabled. TIMx_CCR6 can be written at anytime, the new value is taken in account immediately.; 1=Preload register on TIMx_CCR6 enabled. Read/Write operations access the preload register. TIMx_CCR6 preload value is loaded in the active register at each update event.
  [10] OC6FE — Output compare 6 fast enable
    0=CC6 behaves normally depending on counter and CCR6 values even when the trigger is ON. The minimum delay to activate CC6 output when an edge occurs on the trigger input is 5 clock cycles.; 1=An active edge on the trigger input acts like a compare match on CC6 output. Then, OC is set to the compare level independently from the result of the comparison. Delay to sample the trigger input and to activate CC6 output is reduced to 3 clock cycles. OCFE acts only if the channel is configured in PWM1 or PWM2 mode.
  [7] OC5CE — Output compare 5 clear enable
    0=tim_oc5ref is not affected by the tim_ocref_clr_int signal; 1=tim_oc5ref is cleared as soon as a High level is detected on tim_ocref_clr_int signal (tim_ocref_clr input or tim_etrf input)
  [6:4] OC5M — OC5M[2:0]: Output compare 5 mode
    0=Frozen - The comparison between the output compare register TIMx_CCR5 and the counter TIMx_CNT has no effect on the outputs.(this mode is used to generate a timing base); 1=Set channel 5 to active level on match. tim_oc5ref signal is forced high when the counter TIMx_CNT matches the capture/compare register 5 (TIMx_CCR5).; 2=Set channel 5 to inactive level on match. tim_oc5ref signal is forced low when the counter TIMx_CNT matches the capture/compare register 5 (TIMx_CCR5).; 3=Toggle - tim_oc5ref toggles when TIMx_CNT = TIMx_CCR5; 4=Force inactive level - tim_oc5ref is forced low; 5=Force active level - tim_oc5ref is forced high; 6=PWM mode 1 - In upcounting, channel 5 is active as long as TIMx_CNTless thanTIMx_CCR5 else inactive. In downcounting, channel 5 is inactive (tim_oc5ref = 0) as long as TIMx_CNT>TIMx_CCR5 else active (tim_oc5ref = 1).; 7=PWM mode 2 - In upcounting, channel 5 is inactive as long as TIMx_CNTless thanTIMx_CCR5 else active. In downcounting, channel 5 is active as long as TIMx_CNT>TIMx_CCR5 else inactive.
  [3] OC5PE — Output compare 5 preload enable
    0=Preload register on TIMx_CCR5 disabled. TIMx_CCR5 can be written at anytime, the new value is taken in account immediately.; 1=Preload register on TIMx_CCR5 enabled. Read/Write operations access the preload register. TIMx_CCR5 preload value is loaded in the active register at each update event.
  [2] OC5FE — Output compare 5 fast enable
    0=CC5 behaves normally depending on counter and CCR5 values even when the trigger is ON. The minimum delay to activate CC5 output when an edge occurs on the trigger input is 5 clock cycles.; 1=An active edge on the trigger input acts like a compare match on CC5 output. Then, OC is set to the compare level independently from the result of the comparison. Delay to sample the trigger input and to activate CC5 output is reduced to 3 clock cycles. OCFE acts only if the channel is configured in PWM1 or PWM2 mode.
0x54 TIM_DTR2 — TIM timer deadtime register 2
  [17] DTPE — Deadtime preload enable
    0=Deadtime value is not preloaded; 1=Deadtime value preload is enabled
  [16] DTAE — Deadtime asymmetric enable
    0=Deadtime on rising and falling edges are identical, and defined with DTG[7:0] register; 1=Deadtime on rising edge is defined with DTG[7:0] register and deadtime on falling edge is defined with DTGF[7:0] bits
  [7:0] DTGF — Dead-time falling edge generator setup
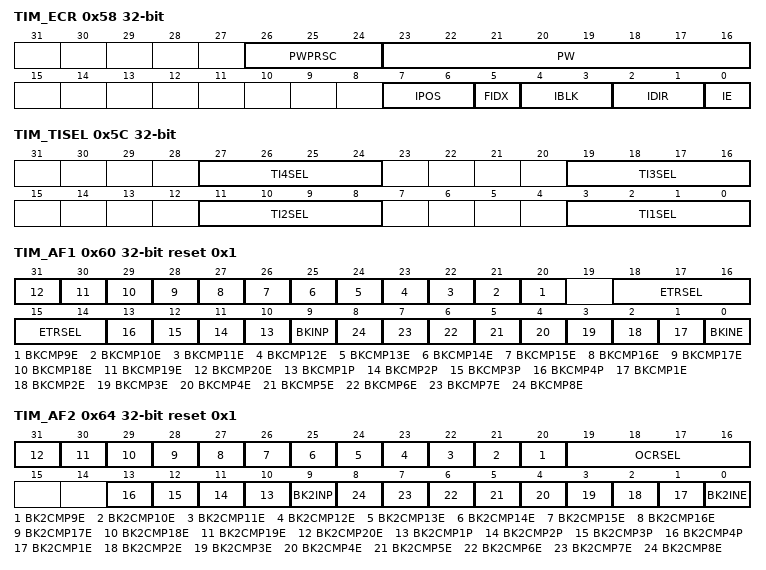
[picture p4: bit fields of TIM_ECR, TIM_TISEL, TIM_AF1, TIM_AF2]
0x58 TIM_ECR — TIM timer encoder control register
  [26:24] PWPRSC — Pulse width prescaler
  [23:16] PW — Pulse width
  [7:6] IPOS — Index positioning
    0=Index resets the counter when AB = 00; 1=Index resets the counter when AB = 01; 2=Index resets the counter when AB = 10; 3=Index resets the counter when AB = 11
  [5] FIDX — First index
    0=Index is always active; 1=the first Index only resets the counter
  [4:3] IBLK — Index blanking
    0=Index always active; 1=Index disabled when tim_ti3 input is active, as per CC3P bit field; 2=Index disabled when tim_ti4 input is active, as per CC4P bit field
  [2:1] IDIR — Index direction
    0=Index resets the counter whatever the direction; 1=Index resets the counter when up-counting only; 2=Index resets the counter when down-counting only
  [0] IE — Index enable
    0=Index disabled; 1=Index enabled
0x5C TIM_TISEL — TIM timer input selection register
  [27:24] TI4SEL — Selects tim_ti4[15:0] input
    0=tim_ti4_in0: TIMx_CH4; 1=tim_ti4_in1; 15=tim_ti4_in15
  [19:16] TI3SEL — Selects tim_ti3[15:0] input
    0=tim_ti3_in0: TIMx_CH2; 1=tim_ti3_in1; 15=tim_ti3_in15
  [11:8] TI2SEL — Selects tim_ti2[15:0] input
    0=tim_ti2_in0: TIMx_CH2; 1=tim_ti2_in1; 15=tim_ti2_in15
  [3:0] TI1SEL — Selects tim_ti1[15:0] input
    0=tim_ti1_in0: TIMx_CH1; 1=tim_ti1_in1; 15=tim_ti1_in15
0x60 TIM_AF1 reset 0x1 — TIM alternate function option register 1
  [n+11] BKCMP{n}E (n=9..20) — tim_brk_cmp{n} enable
    0=tim_brk_cmp{n} input disabled; 1=tim_brk_cmp{n} input enabled
  [18:14] ETRSEL — etr_in source selection
    0=tim_etr0: TIMx_ETR input; 1=tim_etr1; 31=tim_etr31
  [n+9] BKCMP{n}P (n=1..4) — tim_brk_cmp{n} input polarity
    0=tim_brk_cmp{n} input polarity is not inverted (active low if BKP=0, active high if BKP=1); 1=tim_brk_cmp{n} input polarity is inverted (active high if BKP=0, active low if BKP=1)
  [9] BKINP — TIMx_BKIN input polarity
    0=TIMx_BKIN input polarity is not inverted (active low if BKP=0, active high if BKP=1); 1=TIMx_BKIN input polarity is inverted (active high if BKP=0, active low if BKP=1)
  [n] BKCMP{n}E (n=1..8) — tim_brk_cmp{n} enable
    values as BKCMP9E
  [0] BKINE — TIMx_BKIN input enable
    0=TIMx_BKIN input disabled; 1=TIMx_BKIN input enabled
0x64 TIM_AF2 reset 0x1 — TIM alternate function register 2
  [n+11] BK2CMP{n}E (n=9..20) — tim_brk2_cmp{n} enable
    0=tim_brk2_cmp{n} input disabled; 1=tim_brk2_cmp{n} input enabled
  [19:16] OCRSEL — ocref_clr source selection
    0=tim_ocref_clr0; 1=tim_ocref_clr1; 15=tim_ocref_clr15
  [n+9] BK2CMP{n}P (n=1..4) — tim_brk2_cmp{n} input polarity
    0=tim_brk2_cmp{n} input polarity is not inverted (active low if BK2P=0, active high if BK2P=1); 1=tim_brk2_cmp{n} input polarity is inverted (active high if BK2P=0, active low if BK2P=1)
  [9] BK2INP — TIMx_BKIN2 input polarity
    0=TIMx_BKIN2 input polarity is not inverted (active low if BK2P=0, active high if BK2P=1); 1=TIMx_BKIN2 input polarity is inverted (active high if BK2P=0, active low if BK2P=1)
  [n] BK2CMP{n}E (n=1..8) — tim_brk2_cmp{n} enable
    values as BK2CMP9E
  [0] BK2INE — TIMx_BKIN2 input enable
    0=TIMx_BKIN2 input disabled; 1=TIMx_BKIN2 input enabled
0x70 TIM_CCR7 — TIM capture/compare register 7
  [19:0] CCR7 — Capture/compare 7 value
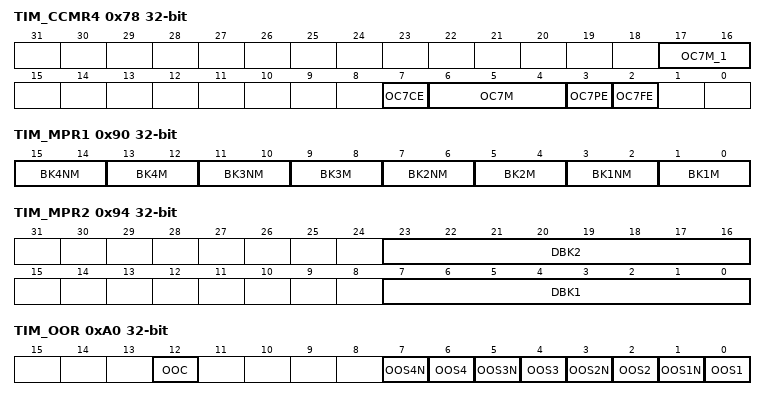
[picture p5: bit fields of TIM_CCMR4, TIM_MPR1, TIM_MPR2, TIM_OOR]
0x78 TIM_CCMR4 — TIM capture/compare mode register 4
  [17:16] OC7M_1 — OC7M[4:3]
  [7] OC7CE — Output compare 7 clear enable
    0=tim_oc7ref is not affected by the tim_ocref_clr_int signal; 1=tim_oc7ref is cleared as soon as a High level is detected on tim_ocref_clr_int signal (tim_ocref_clr input or tim_etrf input)
  [6:4] OC7M — OC7M[2:0]: Output compare 7 mode
    0=Frozen - The comparison between the output compare register TIMx_CCR7 and the counter TIMx_CNT has no effect on the outputs.(this mode is used to generate a timing base); 1=Set channel 7 to active level on match. tim_oc7ref signal is forced high when the counter TIMx_CNT matches the capture/compare register 7 (TIMx_CCR7).; 2=Set channel 7 to inactive level on match. tim_oc7ref signal is forced low when the counter TIMx_CNT matches the capture/compare register 7 (TIMx_CCR7).; 3=Toggle - tim_oc7ref toggles when TIMx_CNT = TIMx_CCR7; 4=Force inactive level - tim_oc7ref is forced low; 5=Force active level - tim_oc7ref is forced high; 6=PWM mode 1 - In upcounting, channel 7 is active as long as TIMx_CNTless thanTIMx_CCR7 else inactive. In downcounting, channel 7 is inactive (tim_oc7ref = 0) as long as TIMx_CNT>TIMx_CCR7 else active (tim_oc5ref = 1).; 7=PWM mode 2 - In upcounting, channel 7 is inactive as long as TIMx_CNTless thanTIMx_CCR7 else active. In downcounting, channel 7 is active as long as TIMx_CNT>TIMx_CCR7 else inactive.
  [3] OC7PE — Output compare 7 preload enable
    0=Preload register on TIMx_CCR7 disabled. TIMx_CCR7 can be written at anytime, the new value is taken in account immediately.; 1=Preload register on TIMx_CCR7 enabled. Read/Write operations access the preload register. TIMx_CCR7 preload value is loaded in the active register at each update event.
  [2] OC7FE — Output compare 7 fast enable
    0=CC7 behaves normally depending on counter and CCR7 values even when the trigger is ON. The minimum delay to activate CC7 output when an edge occurs on the trigger input is 5 clock cycles.; 1=An active edge on the trigger input acts like a compare match on CC7 output. Then, OC is set to the compare level independently from the result of the comparison. Delay to sample the trigger input and to activate CC7 output is reduced to 3 clock cycles. OCFE acts only if the channel is configured in PWM1 or PWM2 mode.
0x90 TIM_MPR1 — TIM multilevel protection register 1
  [all] fields
    0=Immediate break; 1=Delayed 1 break; 2=Delayed 2 break
  [4n-1:4n-2] BK{n}NM (n=1..4) — Break mode for tim_oc{n}n output
  [4n-3:4n-4] BK{n}M (n=1..4) — Break mode for tim_oc{n} output
0x94 TIM_MPR2 — TIM multilevel protection register 2
  [23:16] DBK2 — Delayed 2 Break duration
  [7:0] DBK1 — Delayed 1 Break duration
0xA0 TIM_OOR — TIM output override register
  [12] OOC — Output override control
    0=tim_ocx and tim_ocxn outputs are in the default idle state; 1=tim_ocx and tim_ocxn outputs are forced in an idle state defined with OOSx/OOSxN bits
  [2n-1] OOS{n}N (n=1..4) — Output override state for output tim_oc{n}n
    0=tim_oc{n}n = 0; 1=tim_oc{n}n = 1
  [2n-2] OOS{n} (n=1..4) — Output override state for output tim_oc{n}
    0=tim_oc{n} = 0; 1=tim_oc{n} = 1
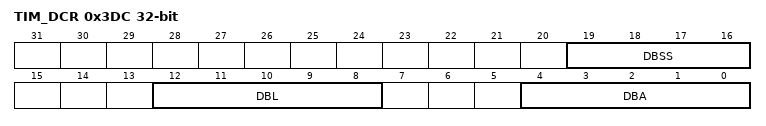
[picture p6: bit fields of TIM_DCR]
0x3DC TIM_DCR — TIM DMA control register
  [19:16] DBSS — DMA burst source selection
    0=Disabled; 1=Update; {v}=CC{v-1} (v=2..5); 6=COM; 7=Trigger
  [12:8] DBL — DMA burst length
    0=1 transfer; 1=2 transfers; 2=3 transfers; 31=32 transfers
  [4:0] DBA — DMA base address
    0=TIMx_CR1; 1=TIMx_CR2; 2=TIMx_SMCR
0x3E0 TIM_DMAR — TIM DMA address for full transfer
  [31:0] DMAB — DMA register for burst accesses
